AUTOSAR XML (schema 4-2-2)
package /ComponentTypes
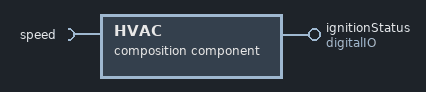
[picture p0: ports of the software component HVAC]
  composition sw component type HVAC
    require port speed: nonqueued-receiver-com-spec=data-element=speed, required-interface=speed
    provide port ignitionStatus: provided-interface=digitalIO
    13 x component:
      SAFace: type=Switch
      SAFoot: type=Switch
      SAWindow: type=Switch
      SAHeatedDriverSeats: type=HeatedSeats
      SAHeatedPassengerSeats: type=HeatedSeats
      SAAirBlow: type=AirBlow
      SAIgnition: type=Ignition
      SAHotColdDriver: type=AirMix
      SAHotColdPassenger: type=AirMix
      SAFaceFoot: type=AirMix
      SAFaceVent: type=AirMix
      SABlowerMotorSpeed: type=AirBlow
      SACabinTemp: type=CabinTempClosedLoop
    delegate SAIgnition.MotorOnOffOut <-> outer port ignitionStatus
